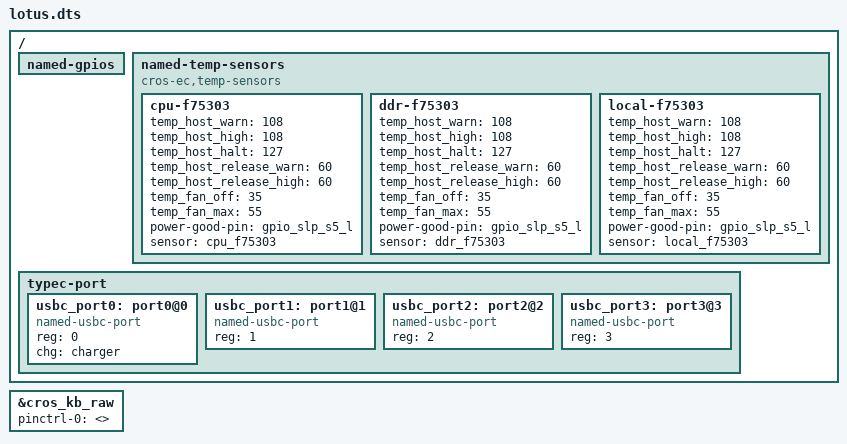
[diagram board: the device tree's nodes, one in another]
/* Copyright 2022 The ChromiumOS Authors
 * Use of this source code is governed by a BSD-style license that can be
 * found in the LICENSE file.
 */

/ {
	named-gpios {
		/* Lotus-specific GPIO customizations */
	};

	named-temp-sensors {
		compatible = "cros-ec,temp-sensors";
		cpu-f75303 {
			temp_host_warn = <108>;
			temp_host_high = <108>;
			temp_host_halt = <127>;
			temp_host_release_warn = <60>;
			temp_host_release_high = <60>;
			temp_fan_off = <35>;
			temp_fan_max = <55>;
			power-good-pin = <&gpio_slp_s5_l>;
			sensor = <&cpu_f75303>;
		};
		ddr-f75303 {
			temp_host_warn = <108>;
			temp_host_high = <108>;
			temp_host_halt = <127>;
			temp_host_release_warn = <60>;
			temp_host_release_high = <60>;
			temp_fan_off = <35>;
			temp_fan_max = <55>;
			power-good-pin = <&gpio_slp_s5_l>;
			sensor = <&ddr_f75303>;
		};
		local-f75303 {
			temp_host_warn = <108>;
			temp_host_high = <108>;
			temp_host_halt = <127>;
			temp_host_release_warn = <60>;
			temp_host_release_high = <60>;
			temp_fan_off = <35>;
			temp_fan_max = <55>;
			power-good-pin = <&gpio_slp_s5_l>;
			sensor = <&local_f75303>;
		};
	};

	typec-port {
		#address-cells = <1>;
		#size-cells = <0>;

		/*
		 * If the CHARGER_SINGLE_CHIP config is enabled, only
		 * one charger chip must be defined.
		 *
		 * In the Zephyer OS, the CONFIG_USB_PD_PORT_MAX_COUNT will check
		 * the device tree compatible "named-usbc-port"
		 */
		usbc_port0: port0@0 {
			compatible = "named-usbc-port";
			reg = <0>;
			chg = <&charger>;
		};
		usbc_port1: port1@1 {
			compatible = "named-usbc-port";
			reg = <1>;
		};
		usbc_port2: port2@2 {
			compatible = "named-usbc-port";
			reg = <2>;
		};
		usbc_port3: port3@3 {
			compatible = "named-usbc-port";
			reg = <3>;
		};
	};
};

&cros_kb_raw {
	status = "okay";
	pinctrl-0 = <>;
	pinctrl-names = "default";
};
